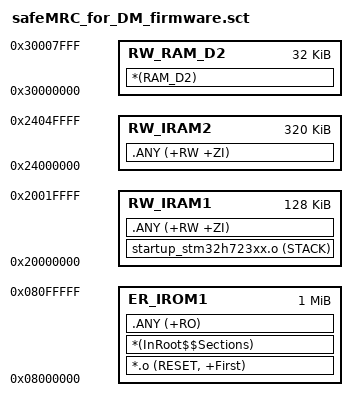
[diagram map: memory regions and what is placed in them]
; *************************************************************
; *** Scatter-Loading Description File — user-maintained    ***
; *************************************************************
;
; STM32H723VGHx memory map:
;   ITCM   0x0000_0000  64 KB  — CPU only, no DMA
;   DTCM   0x2000_0000 128 KB  — CPU only, no DMA (stack lives here)
;   AXI    0x2400_0000 320 KB  — CPU + all DMA masters (cached on H7, but
;                                D-cache is disabled in this project)
;   SRAM1  0x3000_0000  16 KB  \
;   SRAM2  0x3004_0000  16 KB  / D2 SRAM — CPU + DMA1/DMA2, uncached
;   SRAM4  0x3800_0000  16 KB  — D3, BDMA only
;
; Rule: all DMA-accessed buffers must reside in D2 SRAM (RAM_D2 section).

LR_IROM1 0x08000000 0x00100000  {   ; Flash 1 MB

  ER_IROM1 0x08000000 0x00100000  { ; all read-only code/data
   *.o (RESET, +First)
   *(InRoot$$Sections)
   .ANY (+RO)
  }

  ; DTCM 128 KB — zero-wait CPU access; stack here for performance.
  ; WARNING: DMA1/DMA2 cannot access this region.
  RW_IRAM1 0x20000000 0x00020000  {
   startup_stm32h723xx.o (STACK)
   .ANY (+RW +ZI)
  }

  ; AXI SRAM 320 KB — overflow for non-DMA RW/ZI data.
  RW_IRAM2 0x24000000 0x00050000  {
   .ANY (+RW +ZI)
  }

  ; D2 SRAM 32 KB — uncached, accessible by DMA1/DMA2.
  ; All DMA source/destination buffers must carry __attribute__((section("RAM_D2"))).
  RW_RAM_D2 0x30000000 0x00008000  {
   *(RAM_D2)
  }

}
